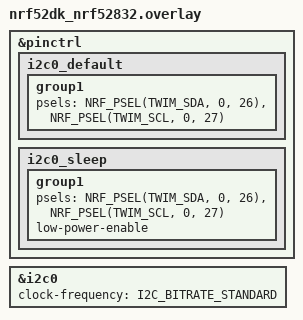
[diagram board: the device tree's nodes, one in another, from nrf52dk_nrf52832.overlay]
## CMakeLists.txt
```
cmake_minimum_required(VERSION 3.20.0)
find_package(Zephyr REQUIRED HINTS $ENV{ZEPHYR_BASE})

project(VCPcontroller)

target_sources(app PRIVATE
    src/main.c
    src/ble_manager.c
    src/vcp_controller.c
    src/battery_reader.c
    src/csip_coordinator.c
    src/app_controller.c
    src/devices_manager.c
    src/has_controller.c
    src/has_settings.c
    src/vcp_settings.c
    src/bas_settings.c
    src/display_manager.c
    src/power_manager.c
    src/button_manager.c
)
```

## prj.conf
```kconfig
CONFIG_BT=y
CONFIG_BT_MAX_CONN=2
CONFIG_BT_MAX_PAIRED=2
CONFIG_BT_DEVICE_NAME="HARC"
CONFIG_BT_CENTRAL=y
CONFIG_BT_BONDABLE=y
CONFIG_BT_SMP=y
CONFIG_BT_SMP_SC_PAIR_ONLY=y
CONFIG_BT_SMP_APP_PAIRING_ACCEPT=y
CONFIG_BT_PRIVACY=y
CONFIG_BT_GATT_AUTO_SEC_REQ=y
CONFIG_BT_FILTER_ACCEPT_LIST=y
CONFIG_BT_RPA_TIMEOUT_DYNAMIC=y

CONFIG_BT_EXT_ADV=y
CONFIG_BT_CTLR_SCAN_DATA_LEN_MAX=255

CONFIG_BT_GATT_CLIENT=y
CONFIG_BT_GATT_AUTO_DISCOVER_CCC=y
CONFIG_BT_GATT_AUTO_UPDATE_MTU=y
CONFIG_BT_GATT_CACHING=y
CONFIG_BT_GATT_SERVICE_CHANGED=y
# Increase GATT resources for multiple concurrent operations
CONFIG_BT_ATT_TX_COUNT=8
CONFIG_BT_ATT_PREPARE_COUNT=4
CONFIG_BT_L2CAP_TX_BUF_COUNT=8
CONFIG_BT_AUDIO=y
CONFIG_BT_VCP_VOL_CTLR=y
CONFIG_BT_CSIP_SET_COORDINATOR=y

# UTF8 support (required by HAS client)
CONFIG_UTF8=y

# Hearing Access Service (HAS) Client support
CONFIG_BT_HAS_CLIENT=y

CONFIG_LOG=y
# Make buffer huge to capture all logs
CONFIG_LOG_BUFFER_SIZE=8192
CONFIG_SYSTEM_WORKQUEUE_STACK_SIZE=4096
CONFIG_MAIN_STACK_SIZE=4096

# Enable heap for k_malloc
CONFIG_HEAP_MEM_POOL_SIZE=4096

# Power Management
CONFIG_PM_DEVICE=y
CONFIG_CRC=y
CONFIG_POWEROFF=y
CONFIG_HWINFO=y

# Enable debug logging
# CONFIG_BT_CONN_LOG_LEVEL_DBG=y
CONFIG_BT_VCP_VOL_CTLR_LOG_LEVEL_DBG=y
# CONFIG_BT_ATT_LOG_LEVEL_DBG=y
# CONFIG_BT_GATT_LOG_LEVEL_DBG=y
# CONFIG_BT_SMP_LOG_LEVEL_DBG=y
# CONFIG_BT_KEYS_LOG_LEVEL_DBG=y
# CONFIG_BT_RPA_LOG_LEVEL_DBG=y
# CONFIG_SETTINGS_LOG_LEVEL_DBG=y
# CONFIG_BT_CSIP_SET_COORDINATOR_LOG_LEVEL_DBG=y
# CONFIG_BT_CSIP_SET_MEMBER_CRYPTO_LOG_LEVEL_DBG=y
# CONFIG_BT_HAS_CLIENT_LOG_LEVEL_DBG=y

CONFIG_BT_SETTINGS=y
CONFIG_SETTINGS=y
CONFIG_FLASH=y
CONFIG_FLASH_MAP=y
CONFIG_NVS=y
CONFIG_FLASH_PAGE_LAYOUT=y
CONFIG_MPU_ALLOW_FLASH_WRITE=y
CONFIG_BT_SETTINGS_CCC_STORE_ON_WRITE=y

# GPIO Support for buttons
CONFIG_GPIO=y

# I2C Support
CONFIG_I2C=y

# Display Support
CONFIG_DISPLAY=y
CONFIG_SSD1306=y

# Character Frame Buffer for text rendering
CONFIG_CHARACTER_FRAMEBUFFER=y

CONFIG_SEGGER_DEBUGMON=y
CONFIG_CORTEX_M_DEBUG_MONITOR_HOOK=y
```

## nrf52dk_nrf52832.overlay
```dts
/*
 * Device Tree Overlay for nRF52DK with nRF52832
 * Configures I2C for OLED display (JMD0.96C)
 * Note: Button aliases (sw0, sw1) are already defined in the base board DTS
 */

/* Pin Configuration for I2C0 */
&pinctrl {
    i2c0_default: i2c0_default {
        group1 {
            psels = <NRF_PSEL(TWIM_SDA, 0, 26)>,
                    <NRF_PSEL(TWIM_SCL, 0, 27)>;
        };
    };

    i2c0_sleep: i2c0_sleep {
        group1 {
            psels = <NRF_PSEL(TWIM_SDA, 0, 26)>,
                    <NRF_PSEL(TWIM_SCL, 0, 27)>;
            low-power-enable;
        };
    };
};

/* I2C0 Configuration for OLED Display */
&i2c0 {
    status = "okay";
    clock-frequency = <I2C_BITRATE_STANDARD>;
};
```

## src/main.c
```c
#include "ble_manager.h"
#include "vcp_controller.h"
#include "csip_coordinator.h"
#include "devices_manager.h"
#include "battery_reader.h"
#include "app_controller.h"
#include "has_controller.h"
#include "display_manager.h"
#include "power_manager.h"
#include "button_manager.h"

LOG_MODULE_REGISTER(main, LOG_LEVEL_INF);

int main(void)
{
    int err;

    if (IS_ENABLED(CONFIG_SETTINGS)) {
        err = settings_subsys_init();
        if (err) {
            LOG_ERR("Settings init failed (err %d)", err);
        } else {
            err = settings_load();
            if (err) {
                LOG_ERR("Settings load failed (err %d)", err);
            }
        }
    }

    err = display_manager_init();
    if (err) {
        LOG_WRN("Display manager init failed (err %d) - continuing without display", err);
    }
    
    err = vcp_controller_init();
	if (err) {
		LOG_ERR("VCP controller init failed (err %d)", err);
		return err;
	}

    err = battery_reader_init();
	if (err)
	{
		LOG_ERR("Battery reader init failed (err %d)", err);
		return err;
	}

	err = csip_coordinator_init();
	if (err)
	{
		LOG_ERR("CSIP coordinator init failed (err %d)", err);
		return err;
	}

    err = has_controller_init();
    if (err) {
        LOG_ERR("HAS controller init failed (err %d)", err);
        return err;
    }

    /* Initialize Bluetooth */
    err = bt_enable(bt_ready_cb);

    while (1) {
        k_sleep(K_SECONDS(1));
    }

    return 0;
}
```

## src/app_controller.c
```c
#include "app_controller.h"
#include "ble_manager.h"
#include "devices_manager.h"
#include "csip_coordinator.h"
#include "has_controller.h"
#include "power_manager.h"
#include "button_manager.h"

LOG_MODULE_REGISTER(app_controller, LOG_LEVEL_DBG);

enum app_event_type {
	EVENT_NONE,
	EVENT_SYSTEM_READY,
	EVENT_DEVICE_CONNECTED,
	EVENT_DEVICE_READY,
	EVENT_DEVICE_DISCONNECTED,
	EVENT_CSIP_DISCOVERED,
	EVENT_CSIP_MEMBER_MATCH,
	EVENT_SCAN_TIMEOUT,
	EVENT_PAIRING_FAILED,
	EVENT_SCAN_COMPLETE,
	EVENT_BAS_DISCOVERED,
	EVENT_VCP_DISCOVERED,
	EVENT_VCP_STATE_READ,
	EVENT_HAS_DISCOVERED,
	EVENT_HAS_PRESETS_READ,
	EVENT_VOLUME_UP_BUTTON_PRESSED,
	EVENT_VOLUME_DOWN_BUTTON_PRESSED,
	EVENT_PAIR_BUTTON_PRESSED,
	EVENT_PRESET_BUTTON_PRESSED,
	EVENT_CLEAR_BONDS_BUTTON_PRESSED,
	EVENT_BONDS_CLEARED,
	EVENT_POWER_OFF,
};

struct app_event {
	enum app_event_type type;
	uint8_t device_id;
	uint8_t error_code;
	void *data;
};

/**
 * @brief Determine connection strategy based on bonded devices
 * @return Connection strategy enum value
 */
static void determine_state(void);

K_MSGQ_DEFINE(app_event_queue, sizeof(struct app_event), 10, 4);

static uint8_t bonded_devices_count = 0;
static enum sm_state state = SM_WAKE;

void app_controller_thread(void)
{
	struct app_event evt;

	LOG_DBG("App thread started");

	state = SM_WAKE;

	while (k_msgq_get(&app_event_queue, &evt, K_FOREVER))
		;
	if (evt.type != EVENT_SYSTEM_READY) {
		LOG_ERR("Expected EVENT_SYSTEM_READY, got %d", evt.type);
		return;
	}

	while (1) {
		switch (state) {
		case SM_IDLE:
			if (button_manager_buttons_ready == false) {
				LOG_DBG("SM_IDLE: Buttons not ready, initializing buttons");
				int err = button_manager_init_buttons();
				if (err) {
					LOG_ERR("Button init failed (err %d)", err);
					continue;
				}
			}

			// Wait for an event to trigger action
			int ret = k_msgq_get(&app_event_queue, &evt, APP_CONTROLLER_ACTION_TIMEOUT);
			if (ret == -EAGAIN) {
				// Timeout, loop back to wait for event for now
				LOG_DBG("SM_IDLE: No event received, entering deep sleep");
				state = SM_POWER_OFF;
				break;
			} else if (ret != 0) {
				LOG_ERR("Failed to get event from queue (err %d)", ret);
				continue;
			}

			switch (evt.type) {
			case EVENT_POWER_OFF:
				LOG_DBG("SM_IDLE: Power off event received");
				state = SM_POWER_OFF;
				break;

            /**
             * Volume up button pressed event
             * In single device operation, send volume up to device 0
             * In dual device operation, send volume up to both devices
             */
			case EVENT_VOLUME_UP_BUTTON_PRESSED:
				LOG_DBG("SM_IDLE: Volume up button pressed");
				if (bonded_devices_count == 1) {
					ble_cmd_vcp_volume_up(
						0,
						false); // Device ID 0 for single device operation
				} else if (bonded_devices_count == 2) {
					ble_cmd_vcp_volume_up(
						0, false); // Device ID 0 for dual device operation
					ble_cmd_vcp_volume_up(
						1, false); // Device ID 1 for dual device operation
				} else {
					LOG_WRN("No connected device to send volume up command, "
						"bonded_devices_count=%d",
						bonded_devices_count);
				}
				break;

            /**
             * Volume down button pressed event
             * In single device operation, send volume down to device 0
             * In dual device operation, send volume down to both devices
             */
			case EVENT_VOLUME_DOWN_BUTTON_PRESSED:
				LOG_DBG("SM_IDLE: Volume down button pressed");
				if (bonded_devices_count == 1) {
					ble_cmd_vcp_volume_down(
						0,
						false); // Device ID 0 for single device operation
				} else if (bonded_devices_count == 2) {
					ble_cmd_vcp_volume_down(
						0, false); // Device ID 0 for dual device operation
					ble_cmd_vcp_volume_down(
						1, false); // Device ID 1 for dual device operation
				} else {
					LOG_WRN("No connected device to send volume down command");
				}
				break;
			
			case EVENT_PRESET_BUTTON_PRESSED:
				LOG_DBG("SM_IDLE: Preset button pressed, going to next preset");
				if (bonded_devices_count == 0) {
					LOG_WRN("No connected device to send preset command");
					break;
				}

				ble_cmd_has_next_preset(0, false); // HI uses synced presets, so only send to one device
				break;

            case EVENT_PAIR_BUTTON_PRESSED:
                LOG_DBG("SM_IDLE: Pair button pressed, clearing bonds and starting first time use procedure");
				button_manager_reset_buttons();

				devices_manager_clear_all_bonds();
				while(k_msgq_get(&app_event_queue, &evt, K_FOREVER));
				if (evt.type != EVENT_BONDS_CLEARED) {
					LOG_ERR("Expected EVENT_BONDS_CLEARED after clearing bonds, got %d", evt.type);
					break;
				}
				
				if (ble_manager_disconnect_device(device_ctx[0].conn) == -EINVAL) {
					LOG_DBG("No active connection to disconnect for device 0");
					app_controller_notify_device_disconnected(0);
				}

				if (ble_manager_disconnect_device(device_ctx[1].conn) == -EINVAL) {
					LOG_DBG("No active connection to disconnect for device 1");
					app_controller_notify_device_disconnected(1);
				}

				while(k_msgq_get(&app_event_queue, &evt, K_FOREVER)); // Wait for device disconnect
				while(k_msgq_get(&app_event_queue, &evt, K_FOREVER)); // Wait for device disconnect

				devices_manager_reset_device_contexts();

                state = SM_WAKE;
                break;
            
            case EVENT_CLEAR_BONDS_BUTTON_PRESSED:
                LOG_DBG("SM_IDLE: Clear bonds button pressed, clearing all bonds");
                devices_manager_clear_all_bonds();
				while(k_msgq_get(&app_event_queue, &evt, K_FOREVER));
				if (evt.type != EVENT_BONDS_CLEARED) {
					LOG_ERR("Expected EVENT_BONDS_CLEARED after clearing bonds, got %d", evt.type);
					break;
				}

                break;

			default:
				LOG_DBG("SM_IDLE: Received event %d", evt.type);
				break;
			}
			break;

		case SM_POWER_OFF:
			LOG_DBG("SM_POWER_OFF: Powering off device");
			power_manager_prepare_power_off();
			while(k_msgq_get(&app_event_queue, &evt, K_FOREVER)); // Wait for device disconnect
			while(k_msgq_get(&app_event_queue, &evt, K_FOREVER)); // Wait for device disconnect
			power_manager_power_off();
			break;

		case SM_WAKE:
			if (power_manager_wake_button == PAIR_BTN_ID) {
				LOG_DBG("SM_WAKE: Wake button is PAIR button, clearing bonds and starting first time use procedure");
				button_manager_reset_buttons();
				devices_manager_clear_all_bonds();
				while(k_msgq_get(&app_event_queue, &evt, K_FOREVER));
				if (evt.type != EVENT_BONDS_CLEARED) {
					LOG_ERR("Expected EVENT_BONDS_CLEARED after clearing bonds, got %d", evt.type);
				}

				state = SM_FIRST_TIME_USE;
				break;
			}

			// Determine connection strategy based on bonded devices
			LOG_DBG("SM_WAKE: Determining state");
			determine_state();
			break;

		case SM_FIRST_TIME_USE:
			LOG_DBG("SM_FIRST_TIME_USE: Starting first time use procedure");
			ble_manager_start_scan_for_HIs();

			/* The ble_manager gets 60 seconds to scan for devices */
			if (k_msgq_get(&app_event_queue, &evt, K_MSEC(BT_SCAN_TIMEOUT_MS)) == 0) {
				if (evt.type == EVENT_SCAN_COMPLETE) {
					uint8_t device_count =
						devices_manager_get_scanned_device_count();
					LOG_INF("Scan complete: %d device(s) found", device_count);

					if (device_count == 0) {
						LOG_WRN("No devices found during scan");
						state = SM_IDLE;
						break;
					}

					devices_manager_print_scanned_devices();
					if (device_count == 1) {
						LOG_INF("Only one device found, selecting it "
							"automatically");
					} else {
						LOG_WRN("Multiple devices found, selecting the "
							"first one for now");
					}
				} else {
					LOG_ERR("Unexpected event %d in SM_FIRST_TIME_USE "
						"(expected EVENT_SCAN_COMPLETE)",
						evt.type);
					state = SM_IDLE;
					break;
				}
			} else {
				LOG_DBG("Timeout waiting for scan completion in SM_FIRST_TIME_USE");
				ble_manager_stop_scan_for_HIs();
				uint8_t device_count = devices_manager_get_scanned_device_count();
				if (device_count == 0) {
					LOG_WRN("No devices found during scan");
					state = SM_IDLE;
					break;
				}

				devices_manager_print_scanned_devices();
				if (device_count == 1) {
					LOG_INF("Only one device found, selecting it "
						"automatically");
				} else {
					LOG_WRN("Multiple devices found, selecting the first one "
						"for now");
				}
			}

			ble_manager_connect_to_scanned_device(
				0, 0); // Connects to first scanned device using Device 0

			/* Now wait for the device to be ready */
			if (k_msgq_get(&app_event_queue, &evt,
				       APP_CONTROLLER_PAIRING_TIMEOUT) == 0) {
				if (evt.type == EVENT_DEVICE_READY) {
					LOG_INF("[DEVICE ID %d] ready, discovering CSIP",
						evt.device_id);
				} else {
					LOG_ERR("Unexpected event %d in SM_FIRST_TIME_USE "
						"(expected EVENT_DEVICE_READY)",
						evt.type);
					state = SM_IDLE;
					break;
				}
			} else {
				LOG_ERR("Timeout waiting for first device to be ready in "
					"SM_FIRST_TIME_USE");
				state = SM_IDLE;
				break;
			}

			ble_cmd_csip_discover(evt.device_id, false);
			while (k_msgq_get(&app_event_queue, &evt, K_FOREVER))
				;
			if (evt.type != EVENT_CSIP_DISCOVERED) {
				LOG_ERR("Unexpected event %d in SM_FIRST_TIME_USE", evt.type);
				state = SM_IDLE;
				break;
			} else {
				LOG_INF("CSIP discovered for device %d, proceeding to RSI scan",
					evt.device_id);
			}

			csip_coordinator_rsi_scan_start(evt.device_id);
			while (k_msgq_get(&app_event_queue, &evt, K_FOREVER))
				;
			if (evt.type != EVENT_CSIP_MEMBER_MATCH) {
				LOG_ERR("Unexpected event %d in SM_FIRST_TIME_USE", evt.type);
				state = SM_IDLE;
			} else {
				if (evt.error_code != 0) {
					LOG_WRN("No CSIP member match found for device %d",
						evt.device_id);
					LOG_INF("Proceeding to single device operation");
					state = SM_BONDED_DEVICES;
					bonded_devices_count = 1;
					break;
				}
			}

			char addr_str[BT_ADDR_LE_STR_LEN];
			bt_addr_le_to_str(evt.data, addr_str, sizeof(addr_str));
			LOG_INF("CSIP member match (%s) found for device %d", addr_str,
				evt.device_id);
			LOG_INF("Bonding to device");

			ble_manager_connect(1, evt.data);
			if (k_msgq_get(&app_event_queue, &evt,
				       APP_CONTROLLER_PAIRING_TIMEOUT) == 0) {
				if (evt.type == EVENT_DEVICE_READY) {
					LOG_INF("[DEVICE ID %d] ready, proceeding to dual device",
						evt.device_id);

					bonded_devices_count = 2;
					state = SM_BONDED_DEVICES;
					break;
				} else {
					LOG_ERR("Unexpected event %d in SM_FIRST_TIME_USE "
						"(expected EVENT_DEVICE_READY)",
						evt.type);
				}
			} else {
				LOG_ERR("Timeout waiting for first device to be ready in "
					"SM_FIRST_TIME_USE");
			}

			state = SM_IDLE;
			break;

		case SM_BONDED_DEVICES:
			LOG_DBG("SM_BONDED_DEVICES: Managing bonded device(s)");

            if (bonded_devices_count == 0) {
                LOG_ERR("No bonded devices count set in SM_BONDED_DEVICES");
                state = SM_IDLE;
                return;
            }

			for (ssize_t i = 0; i < bonded_devices_count; i++) {
				ble_manager_establish_trusted_bond(i);

				if (k_msgq_get(&app_event_queue, &evt,
					       APP_CONTROLLER_PAIRING_TIMEOUT) == 0) {
				} else {
					LOG_ERR("Timeout waiting for device %d to be ready in SM_BONDED_DEVICES", i);
					state = SM_IDLE;
					break;
				}

				if (evt.type != EVENT_DEVICE_READY) {
					LOG_ERR("Unexpected event %d in SM_BONDED_DEVICES", evt.type);
					state = SM_IDLE;
					break;
				} else {
					LOG_INF("[DEVICE ID %d] ready after trusted bond, discovering services", evt.device_id);
				}

				ble_cmd_bas_discover(evt.device_id, false);

				while (k_msgq_get(&app_event_queue, &evt, K_FOREVER))
					;
				if (evt.type != EVENT_BAS_DISCOVERED) {
					LOG_ERR("Unexpected event %d in SM_BONDED_DEVICES",
						evt.type);
					state = SM_IDLE;
				} else {
					LOG_INF("BAS discovered for device %d, reading level",
						evt.device_id);
					ble_cmd_bas_read_level(evt.device_id, false);
				}

				ble_cmd_vcp_discover(evt.device_id, false);

				while (k_msgq_get(&app_event_queue, &evt, K_FOREVER))
					;
				if (evt.type != EVENT_VCP_DISCOVERED) {
					LOG_ERR("Unexpected event %d in SM_BONDED_DEVICES",
						evt.type);
				} else {
					LOG_INF("VCP discovered for device %d", evt.device_id);
				}

                has_controller_reset(evt.device_id);

				/**
				 * The HI uses a synchronized set of presets across all members,
				 * so only need to perform HAS discovery on one device.
				 */
                if (i == 0) {
                    ble_cmd_has_discover(evt.device_id, false);

                    while (k_msgq_get(&app_event_queue, &evt, K_FOREVER));
                    if (evt.type != EVENT_HAS_DISCOVERED) {
                        LOG_ERR("Unexpected event %d in SM_BONDED_DEVICES", evt.type);
                    } else {
						if (evt.error_code != 0) {
							LOG_WRN("HAS discovery failed for device %d",
								evt.device_id);
							if (evt.error_code == 15) {
								LOG_DBG("Attempting to discover HAS again for device %d", evt.device_id);
								ble_cmd_has_discover(evt.device_id, false);
							}
						} else {
							LOG_INF("HAS discovered for device %d", evt.device_id);
						}
                    }
                }

				ble_cmd_vcp_read_state(evt.device_id, false);
				while(k_msgq_get(&app_event_queue, &evt, K_FOREVER));
				if (evt.type != EVENT_VCP_STATE_READ) {
					LOG_ERR("Unexpected event %d in SM_BONDED_DEVICES", evt.type);
				} else {
					LOG_INF("VCP state read for device %d", evt.device_id);
				}
			}

            LOG_DBG("All bonded devices managed, entering idle state");
			state = SM_IDLE;

			switch (power_manager_wake_button) {
			case VOLUME_UP_BTN_ID:
				LOG_DBG("SM_IDLE: Wake button is volume up");
				app_controller_notify_volume_up_button_pressed();
				break;
			case VOLUME_DOWN_BTN_ID:
				LOG_DBG("SM_IDLE: Wake button is volume down");
				app_controller_notify_volume_down_button_pressed();
				break;
			case NEXT_PRESET_BTN_ID:
				LOG_DBG("SM_IDLE: Wake button is next preset");
				app_controller_notify_preset_button_pressed();
				break;
			default:
				LOG_DBG("SM_IDLE: No wake button pressed");
				break;
			}
			power_manager_wake_button = 0;
			break;

		default:
			LOG_ERR("Unknown state %d", state);
			state = SM_POWER_OFF;
			break;
		}
	}
}

static void determine_state(void)
{
	struct bond_collection collection;
	devices_manager_get_bonded_devices_collection(&collection);
    bonded_devices_count = collection.count;

	switch (bonded_devices_count) {
	case 0:
		LOG_INF("No bonded devices found, entering first time use procedure");
		state = SM_FIRST_TIME_USE;
		break;
	case 1: case 2:
		LOG_INF("One or two bonded devices found");
		state = SM_BONDED_DEVICES;
		break;
	default:
		LOG_ERR("Illegal number of bonded devices (%d) found", bonded_devices_count);
		devices_manager_clear_all_bonds();
		state = SM_WAKE;
		break;
	}

	return;
}

K_THREAD_DEFINE(app_controller_thread_id, 2048, app_controller_thread, NULL, NULL, NULL, 5, 0, 0);

int8_t app_controller_notify_system_ready()
{
	LOG_DBG("Notifying system ready");
	struct app_event evt = {.type = EVENT_SYSTEM_READY, .device_id = 0};
	return k_msgq_put(&app_event_queue, &evt, K_NO_WAIT);
}

int8_t app_controller_notify_device_connected(uint8_t device_id)
{
	LOG_DBG("Notifying device connected: device_id=%d", device_id);
	struct app_event evt = {.type = EVENT_DEVICE_CONNECTED, .device_id = device_id};
	return k_msgq_put(&app_event_queue, &evt, K_NO_WAIT);
}

int8_t app_controller_notify_device_disconnected(uint8_t device_id)
{
	LOG_DBG("Notifying device disconnected: device_id=%d", device_id);
	struct app_event evt = {.type = EVENT_DEVICE_DISCONNECTED, .device_id = device_id};
	return k_msgq_put(&app_event_queue, &evt, K_NO_WAIT);
}

int8_t app_controller_notify_device_ready(uint8_t device_id)
{
	struct device_context *ctx = devices_manager_get_device_context_by_id(device_id);
	devices_manager_set_device_state(ctx, CONN_STATE_READY);
	LOG_DBG("Notifying device ready: device_id=%d", device_id);
	struct app_event evt = {.type = EVENT_DEVICE_READY, .device_id = device_id};
	return k_msgq_put(&app_event_queue, &evt, K_NO_WAIT);
}

int8_t app_controller_notify_scan_complete()
{
	LOG_INF("Notifying scan complete");
	struct app_event evt = {
		.type = EVENT_SCAN_COMPLETE,
		.device_id = 0,
	};
	return k_msgq_put(&app_event_queue, &evt, K_NO_WAIT);
}

int8_t app_controller_notify_csip_discovered(uint8_t device_id, int8_t err)
{
	LOG_INF("Notifying CSIP discovered: device_id=%d", device_id);
	struct app_event evt = {
		.type = EVENT_CSIP_DISCOVERED,
		.device_id = device_id,
		.error_code = err,
	};
	return k_msgq_put(&app_event_queue, &evt, K_NO_WAIT);
}

int8_t app_controller_notify_csip_member_match(uint8_t device_id, int8_t err,
					       const bt_addr_le_t *addr)
{
	LOG_INF("Notifying CSIP member match: device_id=%d", device_id);
	struct app_event evt = {.type = EVENT_CSIP_MEMBER_MATCH,
				.device_id = device_id,
				.error_code = err,
				.data = (void *)addr};

	return k_msgq_put(&app_event_queue, &evt, K_NO_WAIT);
}

int8_t app_controller_notify_bas_discovered(uint8_t device_id, int err)
{
	LOG_INF("Notifying BAS discovered: device_id=%d", device_id);
	struct app_event evt = {
		.type = EVENT_BAS_DISCOVERED,
		.device_id = device_id,
		.error_code = err,
	};
	return k_msgq_put(&app_event_queue, &evt, K_NO_WAIT);
}

int8_t app_controller_notify_vcp_discovered(uint8_t device_id, int err)
{
	LOG_INF("Notifying VCP discovered: device_id=%d", device_id);
	struct app_event evt = {
		.type = EVENT_VCP_DISCOVERED,
		.device_id = device_id,
		.error_code = err,
	};
	return k_msgq_put(&app_event_queue, &evt, K_NO_WAIT);
}

int8_t app_controller_notify_vcp_state_read(uint8_t device_id, int err)
{
	LOG_INF("Notifying VCP state read: device_id=%d", device_id);
	struct app_event evt = {
		.type = EVENT_VCP_STATE_READ,
		.device_id = device_id,
		.error_code = err,
	};
	return k_msgq_put(&app_event_queue, &evt, K_NO_WAIT);
}

int8_t app_controller_notify_volume_up_button_pressed()
{
	LOG_DBG("Notifying volume up button pressed");
	struct app_event evt = {
		.type = EVENT_VOLUME_UP_BUTTON_PRESSED,
		.device_id = 0,
	};
	return k_msgq_put(&app_event_queue, &evt, K_NO_WAIT);
}

int8_t app_controller_notify_volume_down_button_pressed()
{
	LOG_DBG("Notifying volume down button pressed");
	struct app_event evt = {
		.type = EVENT_VOLUME_DOWN_BUTTON_PRESSED,
		.device_id = 0,
	};
	return k_msgq_put(&app_event_queue, &evt, K_NO_WAIT);
}

int8_t app_controller_notify_pair_button_pressed()
{
	LOG_DBG("Notifying pair button pressed");
	struct app_event evt = {
		.type = EVENT_PAIR_BUTTON_PRESSED,
		.device_id = 0,
	};
	return k_msgq_put(&app_event_queue, &evt, K_NO_WAIT);
}

int8_t app_controller_notify_preset_button_pressed()
{
	LOG_DBG("Notifying preset button pressed");
	struct app_event evt = {
		.type = EVENT_PRESET_BUTTON_PRESSED,
		.device_id = 0,
	};
	return k_msgq_put(&app_event_queue, &evt, K_NO_WAIT);
}

int8_t app_controller_notify_clear_bonds_button_pressed()
{
	LOG_DBG("Notifying clear bonds button pressed");
	struct app_event evt = {
		.type = EVENT_CLEAR_BONDS_BUTTON_PRESSED,
		.device_id = 0,
	};
	return k_msgq_put(&app_event_queue, &evt, K_NO_WAIT);
}

int8_t app_controller_notify_bonds_cleared()
{
	LOG_DBG("Notifying bonds cleared");
	struct app_event evt = {
		.type = EVENT_BONDS_CLEARED,
		.device_id = 0,
	};
	return k_msgq_put(&app_event_queue, &evt, K_NO_WAIT);
}

int8_t app_controller_notify_has_discovered(uint8_t device_id, int err)
{
	LOG_DBG("Notifying HAS discovered: device_id=%d", device_id);
	struct app_event evt = {
		.type = EVENT_HAS_DISCOVERED,
		.device_id = device_id,
		.error_code = err,
	};
	return k_msgq_put(&app_event_queue, &evt, K_NO_WAIT);
}

int8_t app_controller_notify_has_presets_read(uint8_t device_id, int err)
{
	LOG_DBG("Notifying HAS presets read: device_id=%d", device_id);
	struct app_event evt = {
		.type = EVENT_HAS_PRESETS_READ,
		.device_id = device_id,
		.error_code = err,
	};
	return k_msgq_put(&app_event_queue, &evt, K_NO_WAIT);
}

int8_t app_controller_notify_power_off()
{
	LOG_DBG("Notifying power off");
	struct app_event evt = {
		.type = EVENT_POWER_OFF,
		.device_id = 0,
	};
	return k_msgq_put(&app_event_queue, &evt, K_NO_WAIT);
}
```

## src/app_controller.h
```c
#ifndef CONNECTION_MANAGER_H
#define CONNECTION_MANAGER_H

#include "ble_manager.h"
#include <zephyr/logging/log.h>
#include <zephyr/kernel.h>
#include <zephyr/bluetooth/bluetooth.h>
#include <zephyr/bluetooth/conn.h>
#include <zephyr/settings/settings.h>

/* Connection state machine states for dual-device coordination */
enum sm_state {
    SM_IDLE, /* No active connection process */
    SM_WAKE, /* Wake up and determine state */
    SM_FIRST_TIME_USE, /* First device bonding/discovering */
    SM_BONDED_DEVICES, /* Managing bonded device(s) */
    SM_POWER_OFF, /* Powering off the device */
};

#define APP_CONTROLLER_PAIRING_TIMEOUT K_SECONDS(30)
#define APP_CONTROLLER_ACTION_TIMEOUT K_SECONDS(10)

int8_t app_controller_notify_system_ready();
int8_t app_controller_notify_device_connected(uint8_t device_id);
int8_t app_controller_notify_device_disconnected(uint8_t device_id);
int8_t app_controller_notify_bonds_cleared();
int8_t app_controller_notify_device_ready(uint8_t device_id);
int8_t app_controller_notify_scan_complete();
int8_t app_controller_notify_csip_discovered(uint8_t device_id, int8_t err);
int8_t app_controller_notify_csip_member_match(uint8_t device_id, int8_t err, const bt_addr_le_t *addr);
int8_t app_controller_notify_bas_discovered(uint8_t device_id, int err);
int8_t app_controller_notify_vcp_discovered(uint8_t device_id, int err);
int8_t app_controller_notify_vcp_state_read(uint8_t device_id, int err);
int8_t app_controller_notify_volume_up_button_pressed();
int8_t app_controller_notify_volume_down_button_pressed();
int8_t app_controller_notify_pair_button_pressed();
int8_t app_controller_notify_preset_button_pressed();
int8_t app_controller_notify_clear_bonds_button_pressed();
int8_t app_controller_notify_has_discovered(uint8_t device_id, int err);
int8_t app_controller_notify_has_presets_read(uint8_t device_id, int err);
int8_t app_controller_notify_has_read_presets();
int8_t app_controller_notify_power_off();

#endif /* CONNECTION_MANAGER_H */
```

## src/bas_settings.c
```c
/**
 * @file bas_settings.c
 * @brief BAS handle caching in NVS settings
 */

#include "bas_settings.h"

#include <zephyr/settings/settings.h>
#include <zephyr/logging/log.h>
#include <string.h>

LOG_MODULE_REGISTER(bas_settings, LOG_LEVEL_DBG);

/**
 * @brief Store BAS handles to NVS
 */
int bas_settings_store_handles(const bt_addr_le_t *addr,
                               const struct bt_bas_handles *handles)
{
	if (!addr || !handles) {
		return -EINVAL;
	}

	char addr_str[BT_ADDR_LE_STR_LEN];
	bt_addr_le_to_str(addr, addr_str, sizeof(addr_str));

	/* Create settings key: "harc/device/<addr>/bas_handles" */
	char key[64];
	snprintk(key, sizeof(key), "harc/device/%s/bas_handles", addr_str);

	/* Store handles as binary blob */
	int err = settings_save_one(key, handles, sizeof(*handles));
	if (err) {
		LOG_ERR("Failed to store BAS handles for %s (err %d)", addr_str, err);
		return err;
	}

	LOG_INF("Stored BAS handles for %s", addr_str);
	LOG_INF("  service: 0x%04x-0x%04x", handles->service_handle, handles->service_handle_end);
	LOG_INF("  battery_level: 0x%04x", handles->battery_level_handle);
	return 0;
}

/* Context for settings load callback */
struct bas_load_context {
	struct bt_bas_handles *handles;
	bool found;
};

/* Settings load callback for BAS handles */
static int bas_settings_load_cb(const char *key, size_t len, settings_read_cb read_cb,
                                void *cb_arg, void *param)
{
	struct bas_load_context *ctx = (struct bas_load_context *)param;
	const char *name;

	if (!key) {
		return 0;
	}

	/* Extract the leaf name from the key (after last '/') */
	name = strrchr(key, '/');
	if (name) {
		name++; /* Skip the '/' */
	} else {
		name = key;
	}

	if (strcmp(name, "bas_handles") == 0) {
		if (len == sizeof(struct bt_bas_handles)) {
			read_cb(cb_arg, ctx->handles, sizeof(struct bt_bas_handles));
			ctx->found = true;
		} else {
			LOG_WRN("Invalid BAS handles size: %zu (expected %zu)",
			        len, sizeof(struct bt_bas_handles));
		}
	}

	return 0;
}

/**
 * @brief Load BAS handles from NVS
 */
int bas_settings_load_handles(const bt_addr_le_t *addr,
                              struct bt_bas_handles *handles)
{
	if (!addr || !handles) {
		return -EINVAL;
	}

	char addr_str[BT_ADDR_LE_STR_LEN];
	bt_addr_le_to_str(addr, addr_str, sizeof(addr_str));

	/* Create settings key base for this device */
	char key_base[64];
	snprintk(key_base, sizeof(key_base), "harc/device/%s", addr_str);
	LOG_DBG("Loading BAS handles for %s at %s", addr_str, key_base);

	/* Set up context for callback */
	struct bas_load_context ctx = {
		.handles = handles,
		.found = false,
	};

	/* Load settings for this device */
	int err = settings_load_subtree_direct(key_base, bas_settings_load_cb, &ctx);
	if (err) {
		LOG_DBG("Failed to load settings for %s (err %d)", addr_str, err);
		return -ENOENT;
	}

	if (!ctx.found) {
		LOG_DBG("BAS handles not found for %s", addr_str);
		return -ENOENT;
	}

	LOG_INF("Loaded BAS handles for %s", addr_str);
	LOG_INF("  service: 0x%04x-0x%04x", handles->service_handle, handles->service_handle_end);
	LOG_INF("  battery_level: 0x%04x", handles->battery_level_handle);
	return 0;
}

/**
 * @brief Clear BAS handles from NVS
 */
int bas_settings_clear_handles(const bt_addr_le_t *addr)
{
	if (!addr) {
		return -EINVAL;
	}

	char addr_str[BT_ADDR_LE_STR_LEN];
	bt_addr_le_to_str(addr, addr_str, sizeof(addr_str));

	/* Create settings key: "harc/device/<addr>/bas_handles" */
	char key[64];
	snprintk(key, sizeof(key), "harc/device/%s/bas_handles", addr_str);

	/* Delete the setting */
	int err = settings_delete(key);
	if (err) {
		LOG_ERR("Failed to clear BAS handles for %s (err %d)", addr_str, err);
		return err;
	}

	LOG_INF("Cleared BAS handles for %s", addr_str);
	return 0;
}
```

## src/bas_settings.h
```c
/**
 * @file bas_settings.h
 * @brief BAS handle caching in NVS settings
 */

#ifndef BAS_SETTINGS_H_
#define BAS_SETTINGS_H_

#include <zephyr/bluetooth/bluetooth.h>
#include <stdint.h>

/**
 * @brief BAS handles structure for caching
 */
struct bt_bas_handles {
	uint16_t service_handle;
	uint16_t service_handle_end;
	uint16_t battery_level_handle;
};

/**
 * @brief Store BAS handles to NVS
 *
 * @param addr Bluetooth address of the device
 * @param handles BAS handles structure to store
 * @return 0 on success, negative errno on failure
 */
int bas_settings_store_handles(const bt_addr_le_t *addr,
                               const struct bt_bas_handles *handles);

/**
 * @brief Load BAS handles from NVS
 *
 * @param addr Bluetooth address of the device
 * @param handles Buffer to store loaded handles
 * @return 0 on success, -ENOENT if not found, negative errno on failure
 */
int bas_settings_load_handles(const bt_addr_le_t *addr,
                              struct bt_bas_handles *handles);

/**
 * @brief Clear BAS handles from NVS
 *
 * @param addr Bluetooth address of the device
 * @return 0 on success, negative errno on failure
 */
int bas_settings_clear_handles(const bt_addr_le_t *addr);

#endif /* BAS_SETTINGS_H_ */
```

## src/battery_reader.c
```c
#include "battery_reader.h"
#include "bas_settings.h"
#include "devices_manager.h"
#include "app_controller.h"
#include "display_manager.h"

LOG_MODULE_REGISTER(battery_reader, LOG_LEVEL_DBG);

/* Global state variables */
bool battery_discovered = false;
uint8_t battery_level = 0;

/* Read callback for battery level characteristic */
static uint8_t battery_read_cb(struct bt_conn *conn, uint8_t err,
							   struct bt_gatt_read_params *params,
							   const void *data, uint16_t length)
{
	struct device_context *ctx = devices_manager_get_device_context_by_conn(conn);

	if (err)
	{
		LOG_ERR("Battery level read failed (err %u) [DEVICE ID %d]", err, ctx->device_id);
		return BT_GATT_ITER_STOP;
	}

	if (!data)
	{
		LOG_DBG("Battery level read complete [DEVICE ID %d]", ctx->device_id);
		return BT_GATT_ITER_STOP;
	}

	if (length != 1)
	{
		LOG_WRN("Unexpected battery level length: %u [DEVICE ID %d]", length, ctx->device_id);
		return BT_GATT_ITER_STOP;
	}

	ctx->bas_ctlr.battery_level = *(uint8_t *)data;
	LOG_INF("Battery level read: %u%% [DEVICE ID %d]", ctx->bas_ctlr.battery_level, ctx->device_id);

	/* Update display with battery level */
	display_manager_update_battery(ctx->device_id, ctx->bas_ctlr.battery_level);

	ble_cmd_complete(ctx->device_id, 0);

	return BT_GATT_ITER_STOP;
}

/* Read parameters for battery level */
static struct bt_gatt_read_params battery_read_params = {
	.func = battery_read_cb,
	.handle_count = 1,
};

/* Discovery callback for Battery Service characteristics */
static uint8_t discover_char_cb(struct bt_conn *conn,
                                 const struct bt_gatt_attr *attr,
                                 struct bt_gatt_discover_params *params)
{
	struct device_context *ctx = devices_manager_get_device_context_by_conn(conn);
	struct bt_gatt_chrc *chrc;
	
	if (!attr) {
		LOG_DBG("Discovery complete for type %d [DEVICE ID %d]", params->type, ctx->device_id);

		/* If we have the characteristic handle, mark discovery as complete */
		if (ctx->bas_ctlr.battery_level_handle != 0) {
			ctx->info.bas_discovered = true;

			/* Cache handles for future reconnections */
			struct bt_bas_handles handles = {
				.service_handle = ctx->bas_ctlr.battery_service_handle,
				.service_handle_end = ctx->bas_ctlr.battery_service_handle_end,
				.battery_level_handle = ctx->bas_ctlr.battery_level_handle,
			};
			bas_settings_store_handles(&ctx->info.addr, &handles);

			// Complete the discovery command
			LOG_DBG("Battery Service discovery complete (handle: 0x%04x, CCC: 0x%04x) [DEVICE ID %d]",
			        ctx->bas_ctlr.battery_level_handle, ctx->bas_ctlr.battery_level_ccc_handle, ctx->device_id);

			app_controller_notify_bas_discovered(ctx->device_id, 0);
			ble_cmd_complete(ctx->device_id, 0);
		} else {
			LOG_ERR("Battery Service discovery completed but no characteristic found [DEVICE ID %d]", ctx->device_id);
			app_controller_notify_bas_discovered(ctx->device_id, -EINVAL);
			ble_cmd_complete(ctx->device_id, -EINVAL);
		}

		return BT_GATT_ITER_STOP;
	}

	LOG_DBG("[ATTRIBUTE] handle 0x%04X [DEVICE ID %d]", attr->handle, ctx->device_id);

	if (params->type == BT_GATT_DISCOVER_CHARACTERISTIC) {
		chrc = (struct bt_gatt_chrc *)attr->user_data;
		
		if (!bt_uuid_cmp(chrc->uuid, BT_UUID_BAS_BATTERY_LEVEL)) {
			LOG_DBG("Found Battery Level characteristic at handle 0x%04X (properties 0x%02X) [DEVICE ID %d]", chrc->value_handle, chrc->properties, ctx->device_id);
			ctx->bas_ctlr.battery_level_handle = chrc->value_handle;

			// return BT_GATT_ITER_STOP;
		}
	}

	return BT_GATT_ITER_CONTINUE;
}

/* Discovery callback for Battery Service */
static uint8_t discover_service_cb(struct bt_conn *conn,
								   const struct bt_gatt_attr *attr,
								   struct bt_gatt_discover_params *params)
{
	struct device_context *ctx = devices_manager_get_device_context_by_conn(conn);

	if (!attr)
	{
		LOG_WRN("Battery Service not found [DEVICE ID %d]", ctx->device_id);
		return BT_GATT_ITER_STOP;
	}

	struct bt_gatt_service_val *svc = (struct bt_gatt_service_val *)attr->user_data;

	LOG_DBG("Found Battery Service at handle 0x%04X-0x%04X [DEVICE ID %d]", attr->handle, svc->end_handle, ctx->device_id);
	ctx->bas_ctlr.battery_service_handle = attr->handle;
	ctx->bas_ctlr.battery_service_handle_end = svc->end_handle;
	LOG_DBG("Discover characteristics within Battery Service [DEVICE ID %d]", ctx->device_id);

	static struct bt_gatt_discover_params discover_params;
	memset(&discover_params, 0, sizeof(discover_params));
	discover_params.uuid = NULL;
	discover_params.type = BT_GATT_DISCOVER_CHARACTERISTIC;
	discover_params.start_handle = attr->handle + 1;
	discover_params.end_handle = svc->end_handle;
	discover_params.func = discover_char_cb;

	int err = bt_gatt_discover(conn, &discover_params);
	if (err)
	{
		LOG_ERR("Failed to discover characteristics (err %d) [DEVICE ID %d]", err, ctx->device_id);
	}

	return BT_GATT_ITER_STOP;
}

/* Discover Battery Service on connected device */
int battery_discover(uint8_t device_id)
{
	struct device_context *ctx = devices_manager_get_device_context_by_id(device_id);

	if (!ctx || !ctx->conn)
	{
		LOG_ERR("Invalid connection context [DEVICE ID %d]", ctx->device_id);
		return -EINVAL;
	}

	if (ctx->state != CONN_STATE_READY)
	{
		LOG_WRN("Not starting Battery Service discovery - wrong state: %d [DEVICE ID %d]", ctx->state, ctx->device_id);
		return -EINVAL;
	}

	LOG_DBG("Starting Battery Service discovery [DEVICE ID %d]", ctx->device_id);

	if (!ctx->info.bas_discovered)
	{
		/* Try to load cached handles first */
		struct bt_bas_handles cached_handles;
		int load_err = bas_settings_load_handles(&ctx->info.addr, &cached_handles);
		if (load_err == 0) {
			LOG_INF("Loaded cached BAS handles - skipping discovery [DEVICE ID %d]", device_id);
			ctx->bas_ctlr.battery_service_handle = cached_handles.service_handle;
			ctx->bas_ctlr.battery_service_handle_end = cached_handles.service_handle_end;
			ctx->bas_ctlr.battery_level_handle = cached_handles.battery_level_handle;
			ctx->info.bas_discovered = true;

			app_controller_notify_bas_discovered(ctx->device_id, 0);
			ble_cmd_complete(ctx->device_id, 0);
			return 0;
		}

		/* No cached handles, perform full discovery */
		static struct bt_gatt_discover_params discover_params;
		memset(&discover_params, 0, sizeof(discover_params));
		discover_params.uuid = BT_UUID_BAS;
		discover_params.type = BT_GATT_DISCOVER_PRIMARY;
		discover_params.start_handle = BT_ATT_FIRST_ATTRIBUTE_HANDLE;
		discover_params.end_handle = BT_ATT_LAST_ATTRIBUTE_HANDLE;
		discover_params.func = discover_service_cb;

		int err = bt_gatt_discover(ctx->conn, &discover_params);
		if (err)
		{
			LOG_ERR("Battery Service discovery failed (err %d) [DEVICE ID %d]", err, ctx->device_id);
			return err;
		}
	} else {
		LOG_DBG("Battery Service already discovered [DEVICE ID %d]", ctx->device_id);
	}

	return 0;
}

/* Read battery level */
int battery_read_level(uint8_t device_id)
{
	struct device_context *ctx = devices_manager_get_device_context_by_id(device_id);
	
	if (!ctx->conn)
	{
		LOG_ERR("Invalid connection [DEVICE ID %d]", ctx->device_id);
		return -EINVAL;
	}

	if (!ctx->info.bas_discovered || ctx->bas_ctlr.battery_level_handle == 0)
	{
		LOG_WRN("Battery Service not discovered [DEVICE ID %d]", ctx->device_id);
		return -ENOENT;
	}

	LOG_DBG("Reading battery level from handle 0x%04X [DEVICE ID %d]", ctx->bas_ctlr.battery_level_handle, ctx->device_id);

	battery_read_params.single.handle = ctx->bas_ctlr.battery_level_handle;
	battery_read_params.single.offset = 0;

	int err = bt_gatt_read(ctx->conn, &battery_read_params);
	if (err)
	{
		LOG_ERR("Battery level read failed (err %d) [DEVICE ID %d]", err, ctx->device_id);
		return err;
	}

	return 0;
}

/* Reset battery reader state */
void battery_reader_reset(uint8_t device_id)
{
	struct device_context *ctx = devices_manager_get_device_context_by_id(device_id);

	ctx->info.bas_discovered = false;
	ctx->bas_ctlr.battery_level_handle = 0;
	ctx->bas_ctlr.battery_level_ccc_handle = 0;
	ctx->bas_ctlr.battery_level = 0;
	LOG_DBG("Battery reader state reset [DEVICE ID %d]", ctx->device_id);
}

int battery_reader_init(void) {
	// This does nothing but I wanted consistency lol, feel free to remove if you want :)
	LOG_INF("Battery reader initialized");

	return 0;
}
```

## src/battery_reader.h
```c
#ifndef BATTERY_READER_H
#define BATTERY_READER_H

#include "ble_manager.h"
#include <zephyr/kernel.h>
#include <zephyr/bluetooth/bluetooth.h>
#include <zephyr/bluetooth/conn.h>
#include <zephyr/bluetooth/gatt.h>
#include <zephyr/logging/log.h>

/* Battery Service UUID */
// #define BT_UUID_BAS_VAL 0x180F
#define BT_UUID_BAS BT_UUID_DECLARE_16(BT_UUID_BAS_VAL)

/* Battery Level Characteristic UUID */
// #define BT_UUID_BAS_BATTERY_LEVEL_VAL 0x2A19
#define BT_UUID_BAS_BATTERY_LEVEL BT_UUID_DECLARE_16(BT_UUID_BAS_BATTERY_LEVEL_VAL)

/**
 * @brief Discover Battery Service on a connected device
 * 
 * @return 0 on success, negative error code on failure
 */
int battery_discover(uint8_t device_id);

/**
 * @brief Read battery level from discovered battery service
 * 
 * @param conn Pointer to the BLE connection
 * @return 0 on success, negative error code on failure
 */
int battery_read_level(uint8_t device_id);

/**
 * @brief Subscribe to battery level notifications
 * 
 * @param conn Pointer to the BLE connection
 * @return 0 on success, negative error code on failure
 */
int battery_subscribe_notifications();

/**
 * @brief Reset battery reader state
 */
void battery_reader_reset(uint8_t device_id);

int battery_reader_init();

#endif /* BATTERY_READER_H */
```

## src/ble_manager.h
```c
#ifndef BLE_MANAGER_H
#define BLE_MANAGER_H

#include <zephyr/kernel.h>
#include <zephyr/bluetooth/addr.h>
#include <zephyr/bluetooth/bluetooth.h>
#include <zephyr/bluetooth/conn.h>
#include <zephyr/settings/settings.h>
#include <zephyr/logging/log.h>
#include <zephyr/bluetooth/uuid.h>
#include <zephyr/bluetooth/hci.h>
#include <zephyr/sys/byteorder.h>
#include <zephyr/bluetooth/audio/has.h>
#include <stdint.h>
#include <string.h>

/**
 * @brief Helper macro for fulfilling scanning parameters
 * according to the CAP Connection procedures "Ready for Audio related Peripheral" mode.
 * 
 * This will save power when compared to the default @ref BT_LE_SCAN_ACTIVE.
 * It's only used when scanning for a bondable device. If a device is already bonded, we use 100% duty cycle to scan and connect.
 */
#define BT_LE_SCAN_ACTIVE_CAP_RAP BT_LE_SCAN_PARAM(BT_LE_SCAN_TYPE_ACTIVE, \
            BT_LE_SCAN_OPT_FILTER_DUPLICATE, \
            BT_GAP_SCAN_SLOW_INTERVAL_1, \
            BT_GAP_SCAN_SLOW_WINDOW_1)

#define MAX_DISCOVERED_DEVICES_MEMORY_SIZE 1024 // 1 KB
#define BT_NAME_MAX_LEN 12
#define BT_SECURITY_WANTED BT_SECURITY_L2
#define BT_SCAN_TIMEOUT_MS 10000

/* CSIP Set Information */
#define CSIP_SIRK_SIZE 16

/* Maximum number of presets to support */
#define HAS_MAX_PRESETS 10

/* Struct to hold scan callback user data */
struct scan_callback_data {
	bt_addr_le_t addr;
	int8_t rssi;
	bool is_GN_HI; // Set to true if GN Hearing HI service UUID found (0xFEFE)
	char name[BT_NAME_MAX_LEN];
};

struct bt_bas_ctlr {
    uint16_t battery_service_handle;
    uint16_t battery_service_handle_end;
    uint16_t battery_level_handle;
    uint16_t battery_level_ccc_handle;
    uint8_t battery_level;
};

/* Preset information structure */
struct has_preset_info {
    uint8_t index;
    bool available;
    bool writable;
    char name[BT_HAS_PRESET_NAME_MAX];
};

struct bt_has_ctlr {
    struct bt_has *has;
    uint8_t preset_count;
    uint8_t active_preset_index;
    struct has_preset_info presets[HAS_MAX_PRESETS];
    bool presets_read;
};

struct bt_vcp_ctlr {
    struct bt_vcp_vol_ctlr *vol_ctlr;
    struct {
        uint8_t mute : 1;
        uint8_t volume;
    } state;
};

/* BLE command types */
enum ble_cmd_type {
    BLE_CMD_REQUEST_SECURITY,

    /* VCP commands */
    BLE_CMD_VCP_DISCOVER,
    BLE_CMD_VCP_VOLUME_UP,
    BLE_CMD_VCP_VOLUME_DOWN,
    BLE_CMD_VCP_SET_VOLUME,
    BLE_CMD_VCP_MUTE,
    BLE_CMD_VCP_UNMUTE,
    BLE_CMD_VCP_READ_STATE,
    BLE_CMD_VCP_READ_FLAGS,

    /* Battery Service commands */
    BLE_CMD_BAS_DISCOVER,
    BLE_CMD_BAS_READ_LEVEL,

    /* CSIP commands */
    BLE_CMD_CSIP_DISCOVER,

    /* Hearing Access Service commands */
    BLE_CMD_HAS_DISCOVER,
    BLE_CMD_HAS_READ_PRESETS,
    BLE_CMD_HAS_SET_PRESET,
    BLE_CMD_HAS_NEXT_PRESET,
    BLE_CMD_HAS_PREV_PRESET,
};

/* BLE command structure */
struct ble_cmd {
    uint8_t device_id;
    enum ble_cmd_type type;
    uint8_t d0;  // Data parameter (e.g., volume level)
    uint8_t retry_count;
    sys_snode_t node;  // For linked list
};

/* Command queue configuration */
#define BLE_CMD_QUEUE_SIZE 10
#define BLE_CMD_TIMEOUT_MS 10000

/* BLE manager public functions */
int ble_manager_init(void);
int8_t ble_manager_disable_bt();
int ble_manager_connect(uint8_t device_id, const bt_addr_le_t *addr);
void bt_ready_cb(int err);
void ble_manager_set_device_ctx_battery_level(struct bt_conn *conn, uint8_t level);
void ble_manager_start_scan_for_HIs(void);
void ble_manager_stop_scan_for_HIs(void);
int ble_manager_connect_to_bonded_device(uint8_t device_id);
int ble_manager_autoconnect_to_device_by_addr(uint8_t device_id,const bt_addr_le_t *addr);
int ble_manager_connect_to_scanned_device(uint8_t device_id, uint8_t idx);
void ble_manager_establish_trusted_bond(uint8_t device_id);


/* BLE command queue API */
int ble_cmd_request_security(uint8_t device_id);
int ble_cmd_vcp_discover(uint8_t device_id, bool high_priority);
int ble_cmd_vcp_volume_up(uint8_t device_id, bool high_priority);
int ble_cmd_vcp_volume_down(uint8_t device_id, bool high_priority);
int ble_cmd_vcp_set_volume(uint8_t device_id, uint8_t volume, bool high_priority);
int ble_cmd_vcp_mute(uint8_t device_id, bool high_priority);
int ble_cmd_vcp_unmute(uint8_t device_id, bool high_priority);
int ble_cmd_vcp_read_state(uint8_t device_id, bool high_priority);
int ble_cmd_vcp_read_flags(uint8_t device_id, bool high_priority);

int ble_cmd_bas_discover(uint8_t device_id, bool high_priority);
int ble_cmd_bas_read_level(uint8_t device_id, bool high_priority);

int ble_cmd_csip_discover(uint8_t device_id, bool high_priority);

void ble_cmd_queue_reset(uint8_t queue_id);

void ble_cmd_complete(uint8_t device_id, int err);

/* Connection management */
extern struct bt_conn_cb conn_callbacks;
extern struct bt_conn *auth_conn;
int ble_manager_disconnect_device(struct bt_conn *conn);

/* Connection initiation */
int schedule_auto_connect(uint8_t device_id);

/* HAS command queue API */
int ble_cmd_has_discover(uint8_t device_id, bool high_priority);
int ble_cmd_has_read_presets(uint8_t device_id, bool high_priority);
int ble_cmd_has_set_preset(uint8_t device_id, uint8_t preset_index, bool high_priority);
int ble_cmd_has_next_preset(uint8_t device_id, bool high_priority);
int ble_cmd_has_prev_preset(uint8_t device_id, bool high_priority);
#endif /* BLE_MANAGER_H */
```

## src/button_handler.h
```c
/*
 * Button Handler for nRF52832 DK
 * Header file
 */

#ifndef BUTTON_HANDLER_H
#define BUTTON_HANDLER_H

#include <zephyr/kernel.h>

/* Button callback function type */
typedef void (*button_callback_t)(void);

/* Initialize button handlers */
int button_handler_init(void);

/* Register callbacks for button events */
void button_register_volume_up_callback(button_callback_t callback);
void button_register_volume_down_callback(button_callback_t callback);

#endif /* BUTTON_HANDLER_H */
```

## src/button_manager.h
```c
#ifndef BUTTON_MANAGER_H
#define BUTTON_MANAGER_H

#include <zephyr/kernel.h>
#include <zephyr/bluetooth/bluetooth.h>
#include <zephyr/logging/log.h>
#include <zephyr/drivers/gpio.h>

extern bool button_manager_buttons_ready;

#define VOLUME_UP_BTN_PIN DT_GPIO_PIN(DT_ALIAS(sw0), gpios)
#define VOLUME_DOWN_BTN_PIN DT_GPIO_PIN(DT_ALIAS(sw1), gpios)
#define PAIR_BTN_PIN DT_GPIO_PIN(DT_ALIAS(sw2), gpios)
#define NEXT_PRESET_BTN_PIN DT_GPIO_PIN(DT_ALIAS(sw3), gpios)

#define VOLUME_UP_BTN_ID 1
#define VOLUME_DOWN_BTN_ID 2
#define PAIR_BTN_ID 3
#define NEXT_PRESET_BTN_ID 4

void button1_pressed(const struct device *dev, struct gpio_callback *cb, uint32_t pins);
void button2_pressed(const struct device *dev, struct gpio_callback *cb, uint32_t pins);
void button3_pressed(const struct device *dev, struct gpio_callback *cb, uint32_t pins);
void button4_pressed(const struct device *dev, struct gpio_callback *cb, uint32_t pins);

int button_manager_init_buttons(void);
void button_manager_reset_buttons(void);
void button_manager_set_button_interrupt_mode(uint8_t button_id, gpio_flags_t mode);

#endif /* BUTTON_MANAGER_H */
```
